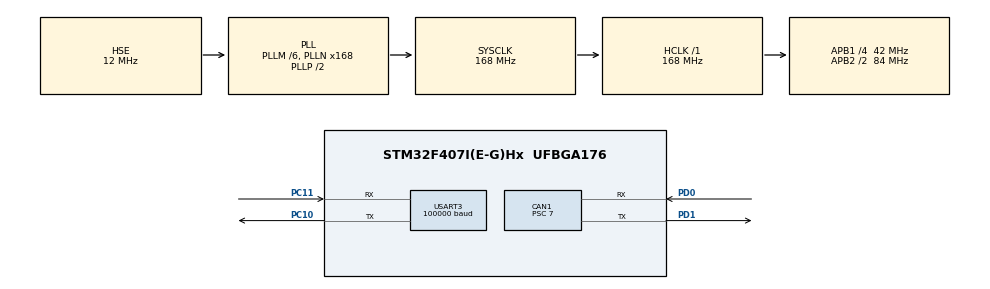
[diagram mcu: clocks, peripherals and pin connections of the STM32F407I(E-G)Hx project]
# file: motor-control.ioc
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CAN1.BS1=CAN_BS1_2TQ
CAN1.BS2=CAN_BS2_3TQ
CAN1.CalculateBaudRate=999999
CAN1.CalculateTimeBit=1000
CAN1.CalculateTimeQuantum=166.66666666666669
CAN1.Prescaler=7
FREERTOS.Tasks01=defaultTask,24,128,StartDefaultTask,Default,NULL,Dynamic,NULL,NULL
Mcu.Family=STM32F4
Mcu.Name=STM32F407I(E-G)Hx
Mcu.Package=UFBGA176
NVIC.CAN1_RX0_IRQn=true\:5\:0\:false\:false\:true\:true\:true\:true\:true
NVIC.PriorityGroup=NVIC_PRIORITYGROUP_4
NVIC.TIM1_UP_TIM10_IRQn=true\:15\:0\:false\:false\:true\:false\:false\:true\:true
NVIC.TimeBase=TIM1_UP_TIM10_IRQn
NVIC.TimeBaseIP=TIM1
NVIC.USART3_IRQn=true\:5\:0\:true\:false\:true\:true\:true\:true\:true
PA13.Mode=Serial_Wire
PA13.Signal=SYS_JTMS-SWDIO
PA14.Mode=Serial_Wire
PA14.Signal=SYS_JTCK-SWCLK
PC10.Mode=Asynchronous
PC10.Signal=USART3_TX
PC11.Mode=Asynchronous
PC11.Signal=USART3_RX
PD0.Mode=CAN_Activate
PD0.Signal=CAN1_RX
PD1.Mode=CAN_Activate
PD1.Signal=CAN1_TX
PH0-OSC_IN.Mode=HSE-External-Oscillator
PH0-OSC_IN.Signal=RCC_OSC_IN
PH1-OSC_OUT.Mode=HSE-External-Oscillator
PH1-OSC_OUT.Signal=RCC_OSC_OUT
ProjectManager.HeapSize=0x200
ProjectManager.StackSize=0x400
ProjectManager.TargetToolchain=CMake
RCC.48MHZClocksFreq_Value=84000000
RCC.AHBFreq_Value=168000000
RCC.APB1CLKDivider=RCC_HCLK_DIV4
RCC.APB1Freq_Value=42000000
RCC.APB1TimFreq_Value=84000000
RCC.APB2CLKDivider=RCC_HCLK_DIV2
RCC.APB2Freq_Value=84000000
RCC.APB2TimFreq_Value=168000000
RCC.CortexFreq_Value=168000000
RCC.HCLKFreq_Value=168000000
RCC.HSE_VALUE=12000000
RCC.HSI_VALUE=16000000
RCC.LSE_VALUE=32768
RCC.PLLM=6
RCC.PLLN=168
RCC.PLLSourceVirtual=RCC_PLLSOURCE_HSE
RCC.SYSCLKFreq_VALUE=168000000
RCC.SYSCLKSource=RCC_SYSCLKSOURCE_PLLCLK
RCC.VCOOutputFreq_Value=336000000
USART3.BaudRate=100000
USART3.Parity=PARITY_EVEN
USART3.VirtualMode=VM_ASYNC
VP_FREERTOS_VS_CMSIS_V2.Mode=CMSIS_V2
VP_SYS_VS_tim1.Mode=TIM1
board=custom

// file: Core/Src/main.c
/* USER CODE BEGIN Header */
/**
 ******************************************************************************
 * @file           : main.c
 * @brief          : Main program body
 ******************************************************************************
 * @attention
 *
 * Copyright (c) 2025 STMicroelectronics.
 * All rights reserved.
 *
 * This software is licensed under terms that can be found in the LICENSE file
 * in the root directory of this software component.
 * If no LICENSE file comes with this software, it is provided AS-IS.
 *
 ******************************************************************************
 */
/* USER CODE END Header */
#include "main.h"
#include "cmsis_os.h"

/* USER CODE BEGIN Includes */
#include "RM3508_motor_contral.h"

/* USER CODE END Includes */

CAN_HandleTypeDef hcan1;

UART_HandleTypeDef huart3;

/* Definitions for defaultTask */
osThreadId_t defaultTaskHandle;
const osThreadAttr_t defaultTask_attributes = {
  .name = "defaultTask",
  .stack_size = 128 * 4,
  .priority = (osPriority_t) osPriorityNormal,
};

void SystemClock_Config(void);
static void MX_GPIO_Init(void);
static void MX_CAN1_Init(void);
static void MX_USART3_UART_Init(void);
void StartDefaultTask(void *argument);

/* USER CODE BEGIN 0 */
/*
uint8_t rx_Buffer[18];
SemaphoreHandle_t temp;
int16_t result;
void HAL_UART_RxCpltCallback(UART_HandleTypeDef *huart)
{

  result = (((int16_t)rx_Buffer[0] | (int16_t)rx_Buffer[1] << 8) & 0x07FF - 1024) ;
	xSemaphoreGiveFromISR(temp,NULL);
  //MotorRm3508Set(0, result);
  //HAL_UART_Receive_IT(&huart3, rx_Buffer, 18);
}

void DR16Process(void *argument)
{
	while(1){
		    xSemaphoreTake(temp, portMAX_DELAY);

	 MotorRm3508Set(0, result);
		HAL_UART_Receive_IT(&huart3, rx_Buffer, 18);
	}
}
*/
/* USER CODE END 0 */

int main(void)
{

  /* MCU Configuration--------------------------------------------------------*/

  /* Reset of all peripherals, Initializes the Flash interface and the Systick. */
  HAL_Init();

  /* Configure the system clock */
  SystemClock_Config();

  /* Initialize all configured peripherals */
  MX_GPIO_Init();
  MX_CAN1_Init();
  MX_USART3_UART_Init();
  /* USER CODE BEGIN 2 */

  // Start receiving data via UART

  // vTaskStartScheduler();

  /* USER CODE END 2 */

  /* Init scheduler */
  osKernelInitialize();

  /* Create the thread(s) */
  /* creation of defaultTask */
  defaultTaskHandle = osThreadNew(StartDefaultTask, NULL, &defaultTask_attributes);

  /* USER CODE BEGIN RTOS_EVENTS */
  /* add events, ... */

  //xTaskCreate(DR16Process, "ControlDR16Process", 512, NULL, 1, NULL);
	//temp = xSemaphoreCreateBinary();
  RM3508PIDMotorInit(&huart3, &hcan1);
	//HAL_UART_Receive_IT(&huart3, rx_Buffer, 18);
  /* USER CODE END RTOS_EVENTS */

  /* Start scheduler */
  osKernelStart();

  /* We should never get here as control is now taken by the scheduler */

  /* Infinite loop */
  /* USER CODE BEGIN WHILE */
  vTaskStartScheduler();

  while (1)
  {
    /* USER CODE END WHILE */

  }
}

void SystemClock_Config(void)
{
  RCC_OscInitTypeDef RCC_OscInitStruct = {0};
  RCC_ClkInitTypeDef RCC_ClkInitStruct = {0};

  /** Configure the main internal regulator output voltage
  */
  __HAL_RCC_PWR_CLK_ENABLE();
  __HAL_PWR_VOLTAGESCALING_CONFIG(PWR_REGULATOR_VOLTAGE_SCALE1);

  /** Initializes the RCC Oscillators according to the specified parameters
  * in the RCC_OscInitTypeDef structure.
  */
  RCC_OscInitStruct.OscillatorType = RCC_OSCILLATORTYPE_HSE;
  RCC_OscInitStruct.HSEState = RCC_HSE_ON;
  RCC_OscInitStruct.PLL.PLLState = RCC_PLL_ON;
  RCC_OscInitStruct.PLL.PLLSource = RCC_PLLSOURCE_HSE;
  RCC_OscInitStruct.PLL.PLLM = 6;
  RCC_OscInitStruct.PLL.PLLN = 168;
  RCC_OscInitStruct.PLL.PLLP = RCC_PLLP_DIV2;
  RCC_OscInitStruct.PLL.PLLQ = 4;
  if (HAL_RCC_OscConfig(&RCC_OscInitStruct) != HAL_OK)
  {
    Error_Handler();
  }

  /** Initializes the CPU, AHB and APB buses clocks
  */
  RCC_ClkInitStruct.ClockType = RCC_CLOCKTYPE_HCLK|RCC_CLOCKTYPE_SYSCLK
                              |RCC_CLOCKTYPE_PCLK1|RCC_CLOCKTYPE_PCLK2;
  RCC_ClkInitStruct.SYSCLKSource = RCC_SYSCLKSOURCE_PLLCLK;
  RCC_ClkInitStruct.AHBCLKDivider = RCC_SYSCLK_DIV1;
  RCC_ClkInitStruct.APB1CLKDivider = RCC_HCLK_DIV4;
  RCC_ClkInitStruct.APB2CLKDivider = RCC_HCLK_DIV2;

  if (HAL_RCC_ClockConfig(&RCC_ClkInitStruct, FLASH_LATENCY_5) != HAL_OK)
  {
    Error_Handler();
  }
}

static void MX_CAN1_Init(void)
{

  hcan1.Instance = CAN1;
  hcan1.Init.Prescaler = 7;
  hcan1.Init.Mode = CAN_MODE_NORMAL;
  hcan1.Init.SyncJumpWidth = CAN_SJW_1TQ;
  hcan1.Init.TimeSeg1 = CAN_BS1_2TQ;
  hcan1.Init.TimeSeg2 = CAN_BS2_3TQ;
  hcan1.Init.TimeTriggeredMode = DISABLE;
  hcan1.Init.AutoBusOff = DISABLE;
  hcan1.Init.AutoWakeUp = DISABLE;
  hcan1.Init.AutoRetransmission = DISABLE;
  hcan1.Init.ReceiveFifoLocked = DISABLE;
  hcan1.Init.TransmitFifoPriority = DISABLE;
  if (HAL_CAN_Init(&hcan1) != HAL_OK)
  {
    Error_Handler();
  }

}

static void MX_USART3_UART_Init(void)
{

  huart3.Instance = USART3;
  huart3.Init.BaudRate = 100000;
  huart3.Init.WordLength = UART_WORDLENGTH_8B;
  huart3.Init.StopBits = UART_STOPBITS_1;
  huart3.Init.Parity = UART_PARITY_EVEN;
  huart3.Init.Mode = UART_MODE_TX_RX;
  huart3.Init.HwFlowCtl = UART_HWCONTROL_NONE;
  huart3.Init.OverSampling = UART_OVERSAMPLING_16;
  if (HAL_UART_Init(&huart3) != HAL_OK)
  {
    Error_Handler();
  }

}

static void MX_GPIO_Init(void)
{

  /* GPIO Ports Clock Enable */
  __HAL_RCC_GPIOA_CLK_ENABLE();
  __HAL_RCC_GPIOD_CLK_ENABLE();
  __HAL_RCC_GPIOC_CLK_ENABLE();
  __HAL_RCC_GPIOH_CLK_ENABLE();

}

void StartDefaultTask(void *argument)
{
  /* USER CODE BEGIN 5 */
  /* Infinite loop */
  for (;;)
  {
    vTaskDelay(1);
  }
  /* USER CODE END 5 */
}

void HAL_TIM_PeriodElapsedCallback(TIM_HandleTypeDef *htim)
{
  if (htim->Instance == TIM1)
  {
    HAL_IncTick();
  }
}

void Error_Handler(void)
{
  __disable_irq();
  while (1)
  {
  }
}
